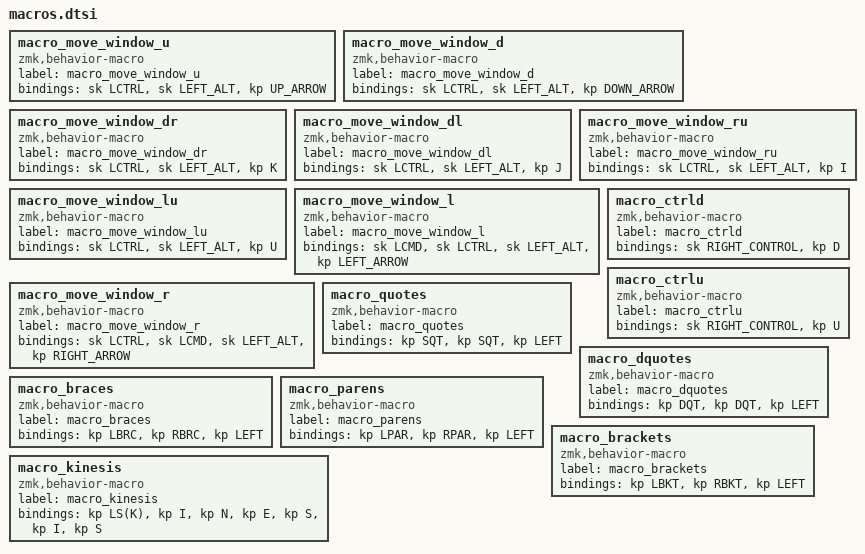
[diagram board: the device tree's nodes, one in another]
macro_move_window_u: macro_move_window_u{
compatible = "zmk,behavior-macro";
label = "macro_move_window_u";
#binding-cells = <0>;
bindings = <&sk LCTRL>, <&sk LEFT_ALT>, <&kp UP_ARROW>;
};
macro_move_window_d: macro_move_window_d{
compatible = "zmk,behavior-macro";
label = "macro_move_window_d";
#binding-cells = <0>;
bindings = <&sk LCTRL>, <&sk LEFT_ALT>, <&kp DOWN_ARROW>;
};
macro_move_window_dr: macro_move_window_dr{
compatible = "zmk,behavior-macro";
label = "macro_move_window_dr";
#binding-cells = <0>;
bindings = <&sk LCTRL>, <&sk LEFT_ALT>, <&kp K>;
};
macro_move_window_dl: macro_move_window_dl{
compatible = "zmk,behavior-macro";
label = "macro_move_window_dl";
#binding-cells = <0>;
bindings = <&sk LCTRL>, <&sk LEFT_ALT>, <&kp J>;
};
macro_move_window_ru: macro_move_window_ru{
compatible = "zmk,behavior-macro";
label = "macro_move_window_ru";
#binding-cells = <0>;
bindings = <&sk LCTRL>, <&sk LEFT_ALT>, <&kp I>;
};
macro_move_window_lu: macro_move_window_lu{
compatible = "zmk,behavior-macro";
label = "macro_move_window_lu";
#binding-cells = <0>;
bindings = <&sk LCTRL>, <&sk LEFT_ALT>, <&kp U>;
};
macro_move_window_l: macro_move_window_l{
compatible = "zmk,behavior-macro";
label = "macro_move_window_l";
#binding-cells = <0>;
bindings = <&sk LCMD>, <&sk LCTRL>, <&sk LEFT_ALT>, <&kp LEFT_ARROW>;
};
macro_move_window_r: macro_move_window_r{
compatible = "zmk,behavior-macro";
label = "macro_move_window_r";
#binding-cells = <0>;
bindings = <&sk LCTRL>, <&sk LCMD>, <&sk LEFT_ALT>, <&kp RIGHT_ARROW>;
};
macro_ctrld: macro_ctrld{
compatible = "zmk,behavior-macro";
label = "macro_ctrld";
#binding-cells = <0>;
bindings = <&sk RIGHT_CONTROL>, <&kp D>;
};
macro_ctrlu: macro_ctrlu{
compatible = "zmk,behavior-macro";
label = "macro_ctrlu";
#binding-cells = <0>;
bindings = <&sk RIGHT_CONTROL>, <&kp U>;
};
macro_quotes: macro_quotes{
compatible = "zmk,behavior-macro";
label = "macro_quotes";
#binding-cells = <0>;
bindings = <&kp SQT>, <&kp SQT>, <&kp LEFT>;
};
macro_dquotes: macro_dquotes{
compatible = "zmk,behavior-macro";
label = "macro_dquotes";
#binding-cells = <0>;
bindings = <&kp DQT>, <&kp DQT>, <&kp LEFT>;
};
macro_braces: macro_braces{
compatible = "zmk,behavior-macro";
label = "macro_braces";
#binding-cells = <0>;
bindings = <&kp LBRC>, <&kp RBRC>, <&kp LEFT>;
};
macro_parens: macro_parens{
compatible = "zmk,behavior-macro";
label = "macro_parens";
#binding-cells = <0>;
bindings = <&kp LPAR>, <&kp RPAR>, <&kp LEFT>;
};
macro_brackets: macro_brackets{
compatible = "zmk,behavior-macro";
label = "macro_brackets";
#binding-cells = <0>;
bindings = <&kp LBKT>, <&kp RBKT>, <&kp LEFT>;
};
macro_kinesis: macro_kinesis{
compatible = "zmk,behavior-macro";
label = "macro_kinesis";
#binding-cells = <0>;
bindings = <&kp LS(K)>, <&kp I>, <&kp N>, <&kp E>, <&kp S>, <&kp I>, <&kp S>;
};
